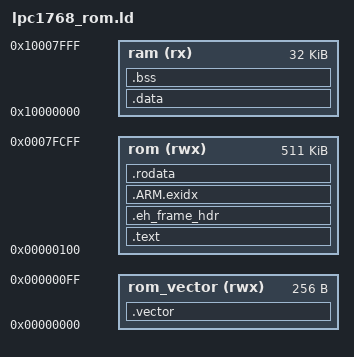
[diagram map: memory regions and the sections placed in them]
/*
* LPC1768のFlash ROM上でプログラムを動かすための最低限度のLDファイル。
* 変数をSRAM上に配置する。Sourcery G++ 2010q1-188の
* Generic-m-hosted.ldを修正して使用。
*/

OUTPUT_FORMAT ("elf32-littlearm", "elf32-bigarm", "elf32-littlearm")
ENTRY(_start)
SEARCH_DIR(.)

MEMORY
{
  rom_vector (rwx) : ORIGIN = 0x00000000, LENGTH = 256
  rom (rwx)        : ORIGIN = 0x00000100, LENGTH = 511K
  ram(rx)          : ORIGIN = 0x10000000, LENGTH = 32K
}


PROVIDE(hardware_init_hook = 0);
PROVIDE(software_init_hook = 0);
PROVIDE(software_term_hook = 0);
STARTUP(start.o)

SECTIONS
{

   _vector_start_lma = ALIGN(8);

  .vector :
  {
  	*(.vector)
  } > rom_vector
  

  .text :
  {
    *(.text .text.* .gnu.linkonce.t.*)
    *(.plt)
    *(.gnu.warning)
    *(.glue_7t) *(.glue_7) *(.vfp11_veneer)

    *(.ARM.extab* .gnu.linkonce.armextab.*)
    *(.gcc_except_table)
  } >rom

  .eh_frame_hdr : ALIGN (4)
  {
    KEEP (*(.eh_frame_hdr))
  } >rom
  
  /* .ARM.exidx is sorted, so has to go in its own output section.  */
  PROVIDE_HIDDEN (__exidx_start = .);
  .ARM.exidx :
  {
    *(.ARM.exidx* .gnu.linkonce.armexidx.*)
  } >rom

  PROVIDE_HIDDEN (__exidx_end = .);

  .rodata : ALIGN (4)
  {
    *(.rodata .rodata.* .gnu.linkonce.r.*)

    . = ALIGN(4);
    KEEP(*(.init))

    . = ALIGN(4);
    __preinit_array_start = .;
    KEEP (*(.preinit_array))
    __preinit_array_end = .;

    . = ALIGN(4);
    __init_array_start = .;
    KEEP (*(SORT(.init_array.*)))
    KEEP (*(.init_array))
    __init_array_end = .;

    . = ALIGN(4);
    KEEP(*(.fini))

    . = ALIGN(4);
    __fini_array_start = .;
    KEEP (*(.fini_array))
    KEEP (*(SORT(.fini_array.*)))
    __fini_array_end = .;

    . = ALIGN(0x4);
    KEEP (*crtbegin.o(.ctors))
    KEEP (*(EXCLUDE_FILE (*crtend.o) .ctors))
    KEEP (*(SORT(.ctors.*)))
    KEEP (*crtend.o(.ctors))

    . = ALIGN(0x4);
    KEEP (*crtbegin.o(.dtors))
    KEEP (*(EXCLUDE_FILE (*crtend.o) .dtors))
    KEEP (*(SORT(.dtors.*)))
    KEEP (*crtend.o(.dtors))

    . = ALIGN (8);
    _etext = .;
  } >rom
  
   __idata_start = ALIGN(8);
  .data : AT (__idata_start )
  {
    . = ALIGN(8);
    __data_start = .;
    KEEP(*(.jcr))
    *(.got.plt) *(.got)
    *(.shdata)
    *(.data .data.* .gnu.linkonce.d.*)
    . = ALIGN (8);
    *(.ram)
    KEEP (*(.eh_frame))
    . = ALIGN(8);
    _edata = .;
  } >ram
  __idata_end = __idata_start + SIZEOF(.data);
    
  .bss : ALIGN(8)
  {
    __bss_start = .;
    *(.shbss)
    *(.bss .bss.* .gnu.linkonce.b.*)
    *(COMMON)
    . = ALIGN (8);
    *(.ram.b .bss.ram)
    _end = .;
    __end = .;
    __bss_end = .;
  } >ram

  .stab 0 (NOLOAD) : { *(.stab) }
  .stabstr 0 (NOLOAD) : { *(.stabstr) }
  /* DWARF debug sections.
   * Symbols in the DWARF debugging sections are relative to
   * the beginning of the section so we begin them at 0.
   */
  /* DWARF 1 */
  .debug          0 : { *(.debug) }
  .line           0 : { *(.line) }
  /* GNU DWARF 1 extensions */
  .debug_srcinfo  0 : { *(.debug_srcinfo) }
  .debug_sfnames  0 : { *(.debug_sfnames) }
  /* DWARF 1.1 and DWARF 2 */
  .debug_aranges  0 : { *(.debug_aranges) }
  .debug_pubnames 0 : { *(.debug_pubnames) }
  /* DWARF 2 */
  .debug_info     0 : { *(.debug_info .gnu.linkonce.wi.*) }
  .debug_abbrev   0 : { *(.debug_abbrev) }
  .debug_line     0 : { *(.debug_line) }
  .debug_frame    0 : { *(.debug_frame) }
  .debug_str      0 : { *(.debug_str) }
  .debug_loc      0 : { *(.debug_loc) }
  .debug_macinfo  0 : { *(.debug_macinfo) }
  /* DWARF 2.1 */
  .debug_ranges   0 : { *(.debug_ranges) }
  /* SGI/MIPS DWARF 2 extensions */
  .debug_weaknames 0 : { *(.debug_weaknames) }
  .debug_funcnames 0 : { *(.debug_funcnames) }
  .debug_typenames 0 : { *(.debug_typenames) }
  .debug_varnames  0 : { *(.debug_varnames) }

  .note.gnu.arm.ident 0 : { KEEP (*(.note.gnu.arm.ident)) }
  .ARM.attributes 0 : { KEEP (*(.ARM.attributes)) }
  /DISCARD/ : { *(.note.GNU-stack) }
}
